# jbr_1986BE9x register map
Registers are 32-bit, access not given, no defined reset value unless marked. A register's access mark holds for its fields unless they carry their own. Addresses are absolute; registers are grouped by the start of their names; [hi:lo] are bit positions; {n}, {i} and the like mark numbered series.

## UART1
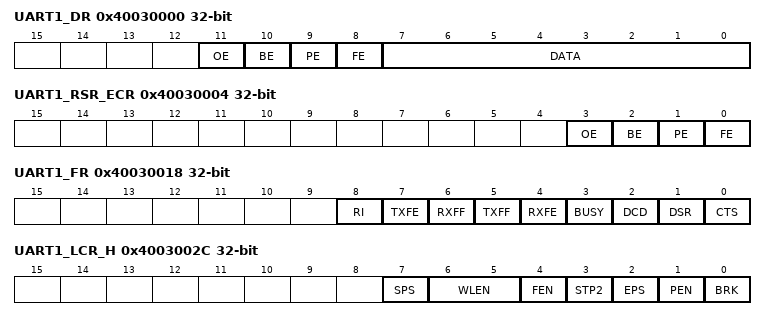
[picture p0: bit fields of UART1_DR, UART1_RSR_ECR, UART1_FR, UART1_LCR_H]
0x40030000 UART1_DR
  [11] OE, [10] BE, [9] PE, [8] FE, [7:0] DATA
0x40030004 UART1_RSR_ECR
  [3] OE, [2] BE, [1] PE, [0] FE
0x40030018 UART1_FR
  [8] RI, [7] TXFE, [6] RXFF, [5] TXFF, [4] RXFE, [3] BUSY, [2] DCD, [1] DSR, [0] CTS
0x40030020 UART1_ILPR
  [7:0] ILPDVSR
0x40030024 UART1_IBRD
  [15:0] BAUDDIV_INT
0x40030028 UART1_FBRD
  [5:0] BAUDDIV_FRAC
0x4003002C UART1_LCR_H
  [7] SPS, [6:5] WLEN, [4] FEN, [3] STP2, [2] EPS, [1] PEN, [0] BRK
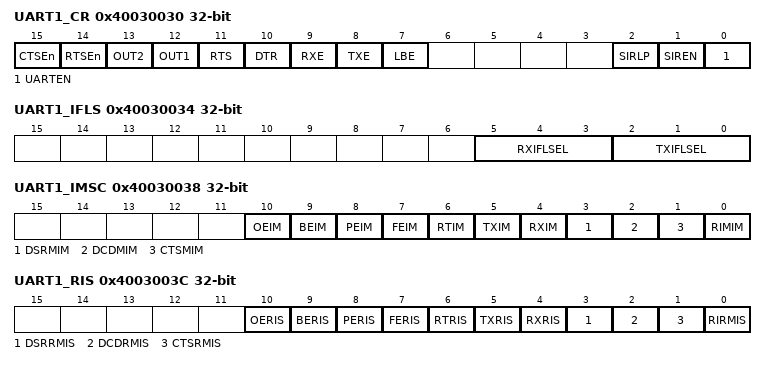
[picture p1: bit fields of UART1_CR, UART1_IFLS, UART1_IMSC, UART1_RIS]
0x40030030 UART1_CR
  [15] CTSEn, [14] RTSEn, [13] OUT2, [12] OUT1, [11] RTS, [10] DTR, [9] RXE, [8] TXE, [7] LBE, [2] SIRLP, [1] SIREN, [0] UARTEN
0x40030034 UART1_IFLS
  [5:3] RXIFLSEL, [2:0] TXIFLSEL
0x40030038 UART1_IMSC
  [10] OEIM, [9] BEIM, [8] PEIM, [7] FEIM, [6] RTIM, [5] TXIM, [4] RXIM, [3] DSRMIM, [2] DCDMIM, [1] CTSMIM, [0] RIMIM
0x4003003C UART1_RIS
  [10] OERIS, [9] BERIS, [8] PERIS, [7] FERIS, [6] RTRIS, [5] TXRIS, [4] RXRIS, [3] DSRRMIS, [2] DCDRMIS, [1] CTSRMIS, [0] RIRMIS
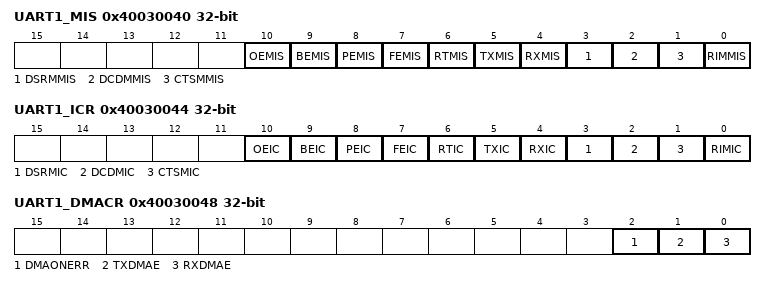
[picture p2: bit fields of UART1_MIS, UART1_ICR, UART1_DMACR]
0x40030040 UART1_MIS
  [10] OEMIS, [9] BEMIS, [8] PEMIS, [7] FEMIS, [6] RTMIS, [5] TXMIS, [4] RXMIS, [3] DSRMMIS, [2] DCDMMIS, [1] CTSMMIS, [0] RIMMIS
0x40030044 UART1_ICR
  [10] OEIC, [9] BEIC, [8] PEIC, [7] FEIC, [6] RTIC, [5] TXIC, [4] RXIC, [3] DSRMIC, [2] DCDMIC, [1] CTSMIC, [0] RIMIC
0x40030048 UART1_DMACR
  [2] DMAONERR, [1] TXDMAE, [0] RXDMAE

## UART2
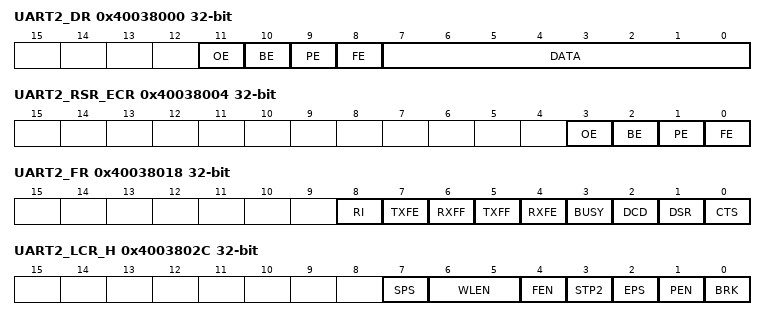
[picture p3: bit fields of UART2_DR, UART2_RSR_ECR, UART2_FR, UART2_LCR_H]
0x40038000 UART2_DR
  [11] OE, [10] BE, [9] PE, [8] FE, [7:0] DATA
0x40038004 UART2_RSR_ECR
  [3] OE, [2] BE, [1] PE, [0] FE
0x40038018 UART2_FR
  [8] RI, [7] TXFE, [6] RXFF, [5] TXFF, [4] RXFE, [3] BUSY, [2] DCD, [1] DSR, [0] CTS
0x40038020 UART2_ILPR
  [7:0] ILPDVSR
0x40038024 UART2_IBRD
  [15:0] BAUDDIV_INT
0x40038028 UART2_FBRD
  [5:0] BAUDDIV_FRAC
0x4003802C UART2_LCR_H
  [7] SPS, [6:5] WLEN, [4] FEN, [3] STP2, [2] EPS, [1] PEN, [0] BRK
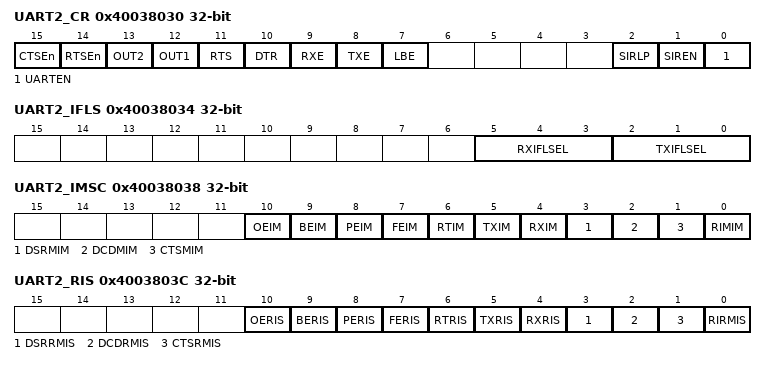
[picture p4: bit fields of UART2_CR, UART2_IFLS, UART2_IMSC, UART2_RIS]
0x40038030 UART2_CR
  [15] CTSEn, [14] RTSEn, [13] OUT2, [12] OUT1, [11] RTS, [10] DTR, [9] RXE, [8] TXE, [7] LBE, [2] SIRLP, [1] SIREN, [0] UARTEN
0x40038034 UART2_IFLS
  [5:3] RXIFLSEL, [2:0] TXIFLSEL
0x40038038 UART2_IMSC
  [10] OEIM, [9] BEIM, [8] PEIM, [7] FEIM, [6] RTIM, [5] TXIM, [4] RXIM, [3] DSRMIM, [2] DCDMIM, [1] CTSMIM, [0] RIMIM
0x4003803C UART2_RIS
  [10] OERIS, [9] BERIS, [8] PERIS, [7] FERIS, [6] RTRIS, [5] TXRIS, [4] RXRIS, [3] DSRRMIS, [2] DCDRMIS, [1] CTSRMIS, [0] RIRMIS
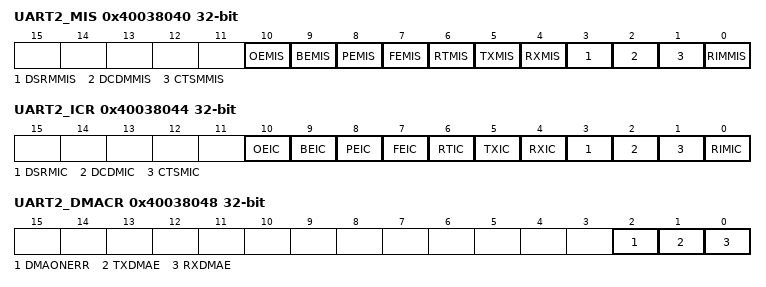
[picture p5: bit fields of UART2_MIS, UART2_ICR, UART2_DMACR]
0x40038040 UART2_MIS
  [10] OEMIS, [9] BEMIS, [8] PEMIS, [7] FEMIS, [6] RTMIS, [5] TXMIS, [4] RXMIS, [3] DSRMMIS, [2] DCDMMIS, [1] CTSMMIS, [0] RIMMIS
0x40038044 UART2_ICR
  [10] OEIC, [9] BEIC, [8] PEIC, [7] FEIC, [6] RTIC, [5] TXIC, [4] RXIC, [3] DSRMIC, [2] DCDMIC, [1] CTSMIC, [0] RIMIC
0x40038048 UART2_DMACR
  [2] DMAONERR, [1] TXDMAE, [0] RXDMAE

## ADC1
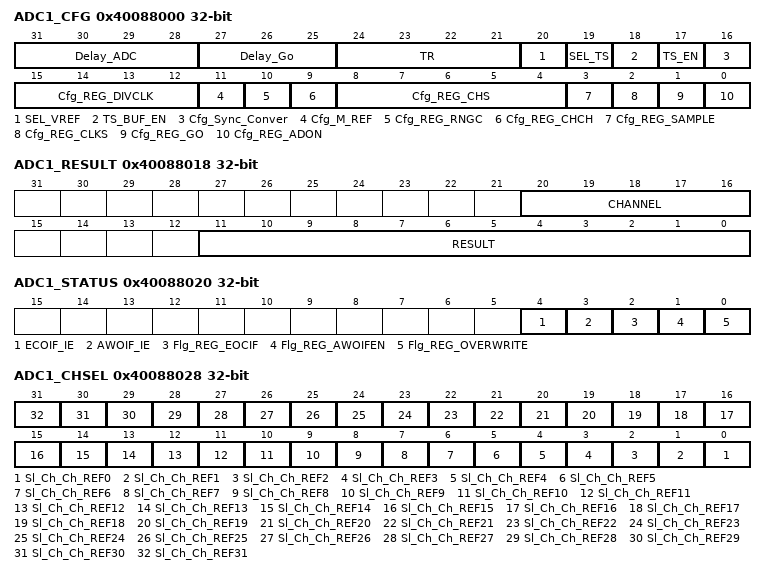
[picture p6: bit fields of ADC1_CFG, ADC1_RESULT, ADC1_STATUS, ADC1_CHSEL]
0x40088000 ADC1_CFG
  [31:28] Delay_ADC, [27:25] Delay_Go, [24:21] TR, [20] SEL_VREF, [19] SEL_TS, [18] TS_BUF_EN, [17] TS_EN, [16] Cfg_Sync_Conver, [15:12] Cfg_REG_DIVCLK, [11] Cfg_M_REF, [10] Cfg_REG_RNGC, [9] Cfg_REG_CHCH, [8:4] Cfg_REG_CHS, [3] Cfg_REG_SAMPLE, [2] Cfg_REG_CLKS, [1] Cfg_REG_GO, [0] Cfg_REG_ADON
0x40088008 ADC1_H_LEVEL
  [11:0] REG_H_LEVEL
0x40088010 ADC1_L_LEVEL
  [11:0] REG_L_LEVEL
0x40088018 ADC1_RESULT
  [20:16] CHANNEL, [11:0] RESULT
0x40088020 ADC1_STATUS
  [4] ECOIF_IE, [3] AWOIF_IE, [2] Flg_REG_EOCIF, [1] Flg_REG_AWOIFEN, [0] Flg_REG_OVERWRITE
0x40088028 ADC1_CHSEL
  [n] Sl_Ch_Ch_REF{n} (n=0..31)

## ADC2
0x40088000 ADC2_CFG
  [11] Cfg_M_REF
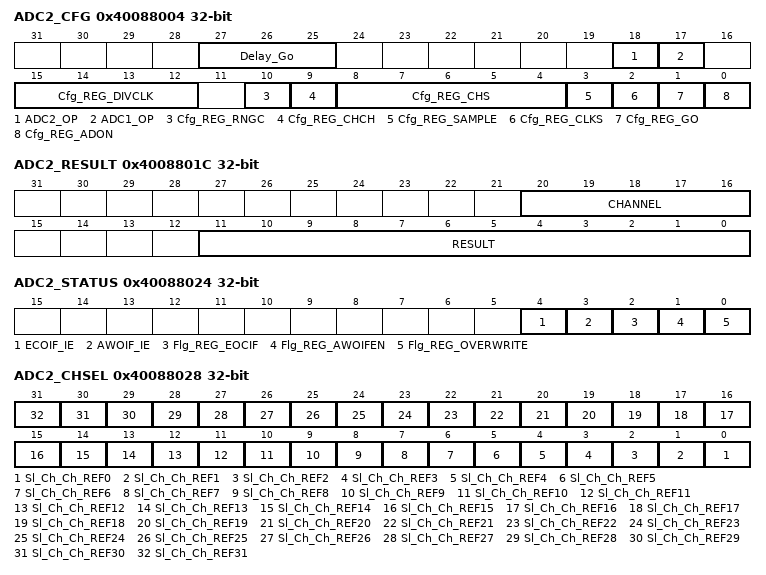
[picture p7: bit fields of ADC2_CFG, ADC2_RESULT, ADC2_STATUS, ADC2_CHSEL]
0x40088004 ADC2_CFG
  [27:25] Delay_Go, [18] ADC2_OP, [17] ADC1_OP, [15:12] Cfg_REG_DIVCLK, [10] Cfg_REG_RNGC, [9] Cfg_REG_CHCH, [8:4] Cfg_REG_CHS, [3] Cfg_REG_SAMPLE, [2] Cfg_REG_CLKS, [1] Cfg_REG_GO, [0] Cfg_REG_ADON
0x4008800C ADC2_H_LEVEL
  [11:0] REG_H_LEVEL
0x40088014 ADC2_L_LEVEL
  [11:0] REG_L_LEVEL
0x4008801C ADC2_RESULT
  [20:16] CHANNEL, [11:0] RESULT
0x40088024 ADC2_STATUS
  [4] ECOIF_IE, [3] AWOIF_IE, [2] Flg_REG_EOCIF, [1] Flg_REG_AWOIFEN, [0] Flg_REG_OVERWRITE
0x40088028 ADC2_CHSEL
  [n] Sl_Ch_Ch_REF{n} (n=0..31)
0x4008802C ADC2_CHSEL
